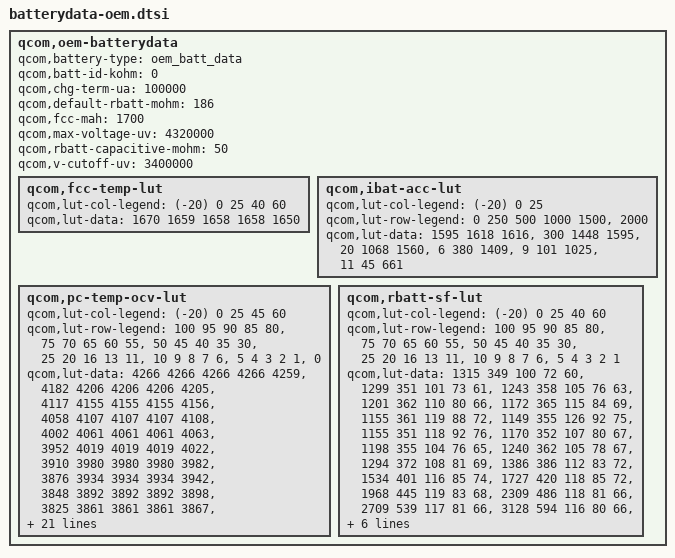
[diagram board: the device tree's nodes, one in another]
/* Copyright (c) 2013-2014, The Linux Foundation. All rights reserved.
 *
 * This program is free software; you can redistribute it and/or modify
 * it under the terms of the GNU General Public License version 2 and
 * only version 2 as published by the Free Software Foundation.
 *
 * This program is distributed in the hope that it will be useful,
 * but WITHOUT ANY WARRANTY; without even the implied warranty of
 * MERCHANTABILITY or FITNESS FOR A PARTICULAR PURPOSE.  See the
 * GNU General Public License for more details.
 */
/*
 * This software is contributed or developed by KYOCERA Corporation.
 * (C) 2016 KYOCERA Corporation
 * (C) 2017 KYOCERA Corporation
 */

qcom,oem-batterydata {
	qcom,battery-type = "oem_batt_data";
	qcom,batt-id-kohm = <0>;
	qcom,chg-term-ua = <100000>;
	qcom,default-rbatt-mohm = <186>;
	qcom,fcc-mah = <1700>;
	qcom,max-voltage-uv = <4320000>;
	qcom,rbatt-capacitive-mohm = <50>;
	qcom,v-cutoff-uv = <3400000>;

	qcom,fcc-temp-lut {
		qcom,lut-col-legend = <(-20) 0 25 40 60>;
		qcom,lut-data = <1670 1659 1658 1658 1650>;
	};

	qcom,ibat-acc-lut {
		qcom,lut-col-legend = <(-20) 0 25>;
		qcom,lut-row-legend = <0 250 500 1000 1500>,
					<2000>;
		qcom,lut-data = <1595 1618 1616>,
						< 300 1448 1595>,
						<  20 1068 1560>,
						<   6  380 1409>,
						<   9  101 1025>,
						<  11   45  661>;
	};

	qcom,pc-temp-ocv-lut {
		qcom,lut-col-legend = <(-20) 0 25 45 60>;
		qcom,lut-row-legend = <100 95 90 85 80>,
					<75 70 65 60 55>,
					<50 45 40 35 30>,
					<25 20 16 13 11>,
					<10 9 8 7 6>,
					<5 4 3 2 1>,
					<0>;
		qcom,lut-data = <4266 4266 4266 4266 4259>,
						<4182 4206 4206 4206 4205>,
						<4117 4155 4155 4155 4156>,
						<4058 4107 4107 4107 4108>,
						<4002 4061 4061 4061 4063>,
						<3952 4019 4019 4019 4022>,
						<3910 3980 3980 3980 3982>,
						<3876 3934 3934 3934 3942>,
						<3848 3892 3892 3892 3898>,
						<3825 3861 3861 3861 3867>,
						<3806 3837 3837 3837 3842>,
						<3788 3816 3816 3816 3821>,
						<3771 3799 3799 3799 3803>,
						<3754 3785 3785 3785 3785>,
						<3736 3771 3771 3771 3764>,
						<3714 3754 3754 3754 3742>,
						<3689 3732 3732 3732 3718>,
						<3662 3710 3710 3710 3696>,
						<3637 3695 3695 3695 3681>,
						<3617 3687 3687 3687 3673>,
						<3607 3684 3684 3684 3669>,
						<3593 3682 3682 3682 3667>,
						<3579 3681 3681 3681 3666>,
						<3563 3679 3679 3679 3665>,
						<3546 3677 3677 3677 3662>,
						<3527 3674 3674 3674 3659>,
						<3505 3666 3666 3666 3649>,
						<3478 3648 3648 3648 3627>,
						<3447 3618 3618 3618 3591>,
						<3409 3578 3578 3578 3546>,
						<3400 3400 3400 3400 3400>;
	};

	qcom,rbatt-sf-lut {
		qcom,lut-col-legend = <(-20) 0 25 40 60>;
		qcom,lut-row-legend = <100 95 90 85 80>,
					<75 70 65 60 55>,
					<50 45 40 35 30>,
					<25 20 16 13 11>,
					<10 9 8 7 6>,
					<5 4 3 2 1>;
		qcom,lut-data = < 1315  349 100 72 60>,
						< 1299  351 101 73 61>,
						< 1243  358 105 76 63>,
						< 1201  362 110 80 66>,
						< 1172  365 115 84 69>,
						< 1155  361 119 88 72>,
						< 1149  355 126 92 75>,
						< 1155  351 118 92 76>,
						< 1170  352 107 80 67>,
						< 1198  355 104 76 65>,
						< 1240  362 105 78 67>,
						< 1294  372 108 81 69>,
						< 1386  386 112 83 72>,
						< 1534  401 116 85 74>,
						< 1727  420 118 85 72>,
						< 1968  445 119 83 68>,
						< 2309  486 118 81 66>,
						< 2709  539 117 81 66>,
						< 3128  594 116 80 66>,
						< 3566  644 117 80 66>,
						< 3794  669 118 80 66>,
						< 4100  700 123 83 68>,
						< 4406  732 127 86 70>,
						< 4807  757 132 89 71>,
						< 5090  780 137 92 73>,
						< 5498  748 138 92 73>,
						< 6504  776 137 90 70>,
						< 8130  860 137 88 68>,
						<10759  999 138 87 68>,
						<15335 1298 141 89 71>;
	};
};
